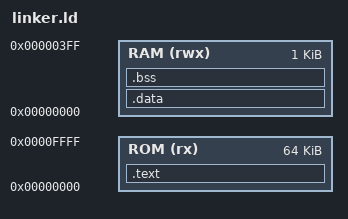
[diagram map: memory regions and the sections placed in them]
ENTRY(_start)

MEMORY
{
    ROM (rx)  : ORIGIN = 0x00000000, LENGTH = 64K
    RAM (rwx) : ORIGIN = 0x00000000, LENGTH = 1K
}

SECTIONS
{
    .text :
    {
        *(.text*)
        *(.rodata*)
    } > ROM

    .data :
    {
        *(.data*)
    } > RAM

    .bss :
    {
        *(.bss*)
        *(COMMON)
    } > RAM

    . = ALIGN(4);

    _stack_top = ORIGIN(RAM) + LENGTH(RAM);
}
